# CLK1_FLAGMUX_CLK1MERGE register map
Vendor: Texas Instruments
Peripheral module from a debugger description file (folder am572x).
Registers are 32-bit, access per field, reset values left out (the file's numbers can be read two ways) unless marked. A register's access mark holds for its fields unless they carry their own. Offsets are as the file gives them; lines under a group give offsets from that group; [hi:lo] are bit positions; {n}, {i} and the like mark numbered series; 'fields as' and 'values as' point back to an identical list; <NAME> marks a mode.

## CLK1_FLAGMUX_CLK1MERGE
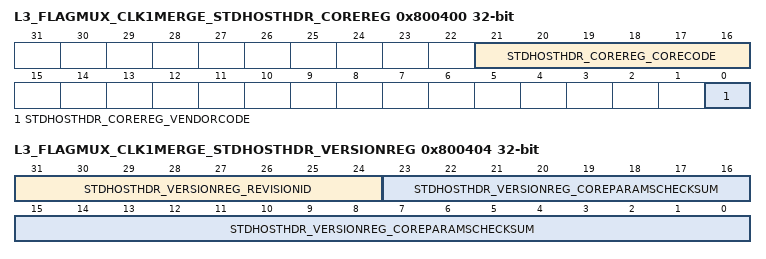
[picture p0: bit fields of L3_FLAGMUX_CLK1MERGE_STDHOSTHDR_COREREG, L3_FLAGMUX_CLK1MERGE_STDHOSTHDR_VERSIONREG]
0x800400 L3_FLAGMUX_CLK1MERGE_STDHOSTHDR_COREREG ro
  [21:16] STDHOSTHDR_COREREG_CORECODE — The Core Code field is a constant reporting a vendor-specific core generator code. Type: Constant. Reset value: 0x37.
  [0] STDHOSTHDR_COREREG_VENDORCODE — The Vendor Code field is a constant reporting the core generator vendor code. Type: Constant. Reset value: 0x1.
    0=Third-party_vendor; 1=STDHOSTHDR_COREREG_VENDORCODE_1_r
0x800404 L3_FLAGMUX_CLK1MERGE_STDHOSTHDR_VERSIONREG ro
  [31:24] STDHOSTHDR_VERSIONREG_REVISIONID — The Revision Identifier field is a constant reporting the core generator revision number. Type: Constant. Reset value: 0x0.
  [23:0] STDHOSTHDR_VERSIONREG_COREPARAMSCHECKSUM — Reserved. Type: Reserved. Reset value: Reserved.
0x800408 L3_FLAGMUX_CLK1MERGE_MASK0
  [1:0] MASK0 rw — Mask flag inputs 0 Type: Control. Reset value: 0x3
0x80040C L3_FLAGMUX_CLK1MERGE_REGERR0
  [1:0] REGERR0 rw — Flag inputs 0 Type: Control. Reset value: X
0x800410 L3_FLAGMUX_CLK1MERGE_MASK1
  [1:0] MASK1 rw — Mask flag inputs 0 Type: Control. Reset value: 0x3
0x800414 L3_FLAGMUX_CLK1MERGE_REGERR1
  [1:0] REGERR1 rw — Flag inputs 0 Type: Control. Reset value: X
